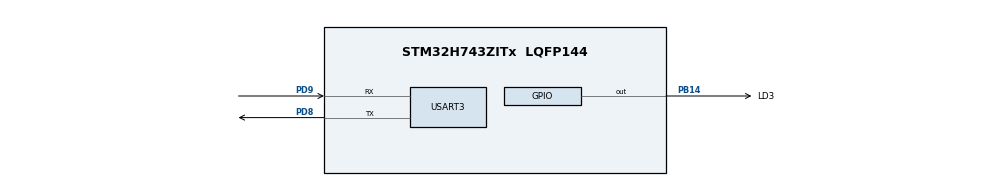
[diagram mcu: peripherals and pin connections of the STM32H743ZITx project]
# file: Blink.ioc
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Mcu.Family=STM32H7
Mcu.Name=STM32H743ZITx
Mcu.Package=LQFP144
NVIC.PriorityGroup=NVIC_PRIORITYGROUP_4
PB14.GPIO_Label=LD3
PB14.Signal=GPIO_Output
PD8.Mode=Asynchronous
PD8.Signal=USART3_TX
PD9.Mode=Asynchronous
PD9.Signal=USART3_RX
ProjectManager.HeapSize=0x200
ProjectManager.StackSize=0x400
ProjectManager.TargetToolchain=MDK-ARM V5
RCC.ADCFreq_Value=129000000
RCC.APB1Freq_Value=120000000
RCC.APB2Freq_Value=120000000
RCC.APB3Freq_Value=120000000
RCC.APB4Freq_Value=120000000
RCC.CortexFreq_Value=480000000
RCC.D1PPRE=RCC_APB3_DIV2
RCC.D2PPRE1=RCC_APB1_DIV2
RCC.D2PPRE2=RCC_APB2_DIV2
RCC.D3PPRE=RCC_APB4_DIV2
RCC.DIVM1=4
RCC.DIVN1=60
RCC.HCLKFreq_Value=240000000
RCC.HPRE=RCC_HCLK_DIV2
RCC.PLL2FRACN=0
RCC.PLL3FRACN=0
RCC.PLLFRACN=0
RCC.SYSCLKFreq_VALUE=480000000
RCC.SYSCLKSource=RCC_SYSCLKSOURCE_PLLCLK
RCC.USBFreq_Value=480000000
USART3.VirtualMode-Asynchronous=VM_ASYNC
board=custom

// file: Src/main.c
/* USER CODE BEGIN Header */
/**
  ******************************************************************************
  * @file           : main.c
  * @brief          : Main program body
  ******************************************************************************
  * @attention
  *
  * <h2><center>&copy; Copyright (c) 2019 STMicroelectronics.
  * All rights reserved.</center></h2>
  *
  * This software component is licensed by ST under BSD 3-Clause license,
  * the "License"; You may not use this file except in compliance with the
  * License. You may obtain a copy of the License at:
  *                        opensource.org/licenses/BSD-3-Clause
  *
  ******************************************************************************
  */
/* USER CODE END Header */

#include "main.h"
#include "usart.h"
#include "gpio.h"

/* USER CODE BEGIN Includes */
#include "Arduino.h"
/* USER CODE END Includes */

void SystemClock_Config(void);

int main(void)
{

  /* MCU Configuration--------------------------------------------------------*/

  /* Reset of all peripherals, Initializes the Flash interface and the Systick. */
  HAL_Init();

  /* Configure the system clock */
  SystemClock_Config();

  /* Initialize all configured peripherals */
  MX_GPIO_Init();
  MX_USART3_UART_Init();
  /* USER CODE BEGIN 2 */
	HAL_UART_Transmit(&huart3,(uint8_t *)">> System initialization...\r\n",29,1000);
	setup();
  /* USER CODE END 2 */

  /* Infinite loop */
  /* USER CODE BEGIN WHILE */
  while (1)
  {
		loop();
    /* USER CODE END WHILE */

  }
}

void SystemClock_Config(void)
{
  RCC_OscInitTypeDef RCC_OscInitStruct = {0};
  RCC_ClkInitTypeDef RCC_ClkInitStruct = {0};
  RCC_PeriphCLKInitTypeDef PeriphClkInitStruct = {0};

  /** Supply configuration update enable
  */
  HAL_PWREx_ConfigSupply(PWR_LDO_SUPPLY);
  /** Configure the main internal regulator output voltage
  */
  __HAL_PWR_VOLTAGESCALING_CONFIG(PWR_REGULATOR_VOLTAGE_SCALE0);

  while(!__HAL_PWR_GET_FLAG(PWR_FLAG_VOSRDY)) {}
  /** Initializes the CPU, AHB and APB busses clocks
  */
  RCC_OscInitStruct.OscillatorType = RCC_OSCILLATORTYPE_HSI;
  RCC_OscInitStruct.HSIState = RCC_HSI_DIV1;
  RCC_OscInitStruct.HSICalibrationValue = RCC_HSICALIBRATION_DEFAULT;
  RCC_OscInitStruct.PLL.PLLState = RCC_PLL_ON;
  RCC_OscInitStruct.PLL.PLLSource = RCC_PLLSOURCE_HSI;
  RCC_OscInitStruct.PLL.PLLM = 4;
  RCC_OscInitStruct.PLL.PLLN = 60;
  RCC_OscInitStruct.PLL.PLLP = 2;
  RCC_OscInitStruct.PLL.PLLQ = 2;
  RCC_OscInitStruct.PLL.PLLR = 2;
  RCC_OscInitStruct.PLL.PLLRGE = RCC_PLL1VCIRANGE_3;
  RCC_OscInitStruct.PLL.PLLVCOSEL = RCC_PLL1VCOWIDE;
  RCC_OscInitStruct.PLL.PLLFRACN = 0;
  if (HAL_RCC_OscConfig(&RCC_OscInitStruct) != HAL_OK)
  {
    Error_Handler();
  }
  /** Initializes the CPU, AHB and APB busses clocks
  */
  RCC_ClkInitStruct.ClockType = RCC_CLOCKTYPE_HCLK|RCC_CLOCKTYPE_SYSCLK
                              |RCC_CLOCKTYPE_PCLK1|RCC_CLOCKTYPE_PCLK2
                              |RCC_CLOCKTYPE_D3PCLK1|RCC_CLOCKTYPE_D1PCLK1;
  RCC_ClkInitStruct.SYSCLKSource = RCC_SYSCLKSOURCE_PLLCLK;
  RCC_ClkInitStruct.SYSCLKDivider = RCC_SYSCLK_DIV1;
  RCC_ClkInitStruct.AHBCLKDivider = RCC_HCLK_DIV2;
  RCC_ClkInitStruct.APB3CLKDivider = RCC_APB3_DIV2;
  RCC_ClkInitStruct.APB1CLKDivider = RCC_APB1_DIV2;
  RCC_ClkInitStruct.APB2CLKDivider = RCC_APB2_DIV2;
  RCC_ClkInitStruct.APB4CLKDivider = RCC_APB4_DIV2;

  if (HAL_RCC_ClockConfig(&RCC_ClkInitStruct, FLASH_LATENCY_4) != HAL_OK)
  {
    Error_Handler();
  }
  PeriphClkInitStruct.PeriphClockSelection = RCC_PERIPHCLK_USART3;
  PeriphClkInitStruct.Usart234578ClockSelection = RCC_USART234578CLKSOURCE_D2PCLK1;
  if (HAL_RCCEx_PeriphCLKConfig(&PeriphClkInitStruct) != HAL_OK)
  {
    Error_Handler();
  }
}

void Error_Handler(void)
{
}

/************************ (C) COPYRIGHT STMicroelectronics *****END OF FILE****/
